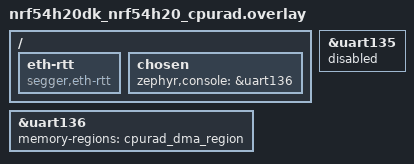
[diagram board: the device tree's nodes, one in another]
/*
 * Copyright (c) 2024 Nordic Semiconductor ASA
 *
 * SPDX-License-Identifier: LicenseRef-Nordic-5-Clause
 */
/ {
	eth-rtt {
		compatible = "segger,eth-rtt";
	};

	chosen {
		zephyr,console = &uart136;
	};
};


&uart136 {
	status = "okay";
	memory-regions = <&cpurad_dma_region>;
};

&uart135 {
	status = "disabled";
};
